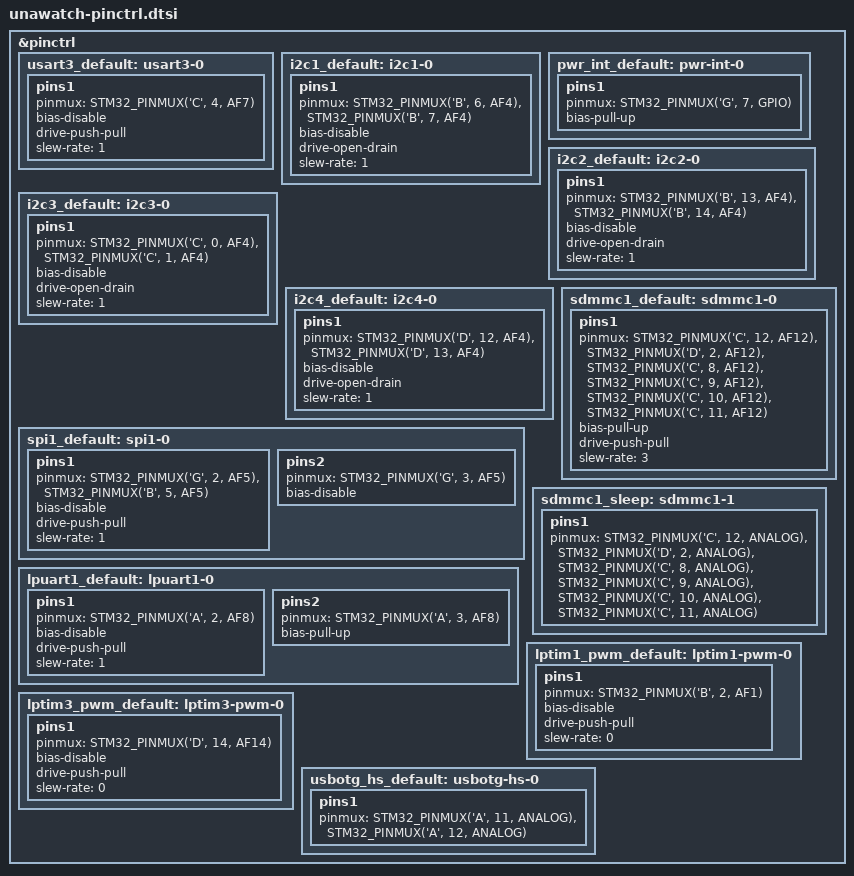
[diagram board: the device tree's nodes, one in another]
// SPDX-FileCopyrightText: 2026 Core Devices LLC
// SPDX-License-Identifier: (GPL-2.0-only OR BSD-2-Clause)

&pinctrl {
	// The debug log, TX only, to the USB-C connector through the USB_DAM switch
	usart3_default: usart3-0 {
		pins1 {
			pinmux = <STM32_PINMUX('C', 4, AF7)>; /* USART3_TX */
			bias-disable;
			drive-push-pull;
			slew-rate = <1>;
		};
	};

	// The main bus, external pull-ups: PMIC, fuel gauge, USB-PD, haptics, display EEPROM
	i2c1_default: i2c1-0 {
		pins1 {
			pinmux = <STM32_PINMUX('B', 6, AF4)>, /* I2C1_SCL */
				 <STM32_PINMUX('B', 7, AF4)>; /* I2C1_SDA */
			bias-disable;
			drive-open-drain;
			slew-rate = <1>;
		};
	};

	// PWR_INT_L: the PMIC's INTB and the STUSB4500's ALERT, open drain
	pwr_int_default: pwr-int-0 {
		pins1 {
			pinmux = <STM32_PINMUX('G', 7, GPIO)>;
			bias-pull-up;
		};
	};

	// The body module: PPG, barometer, EEPROM
	i2c2_default: i2c2-0 {
		pins1 {
			pinmux = <STM32_PINMUX('B', 13, AF4)>, /* I2C2_SCL */
				 <STM32_PINMUX('B', 14, AF4)>; /* I2C2_SDA */
			bias-disable;
			drive-open-drain;
			slew-rate = <1>;
		};
	};

	// The BLE module: its EEPROM
	i2c3_default: i2c3-0 {
		pins1 {
			pinmux = <STM32_PINMUX('C', 0, AF4)>, /* I2C3_SCL */
				 <STM32_PINMUX('C', 1, AF4)>; /* I2C3_SDA */
			bias-disable;
			drive-open-drain;
			slew-rate = <1>;
		};
	};

	// The GPS/IMU module: EEPROM, BMI270, BMM350
	i2c4_default: i2c4-0 {
		pins1 {
			pinmux = <STM32_PINMUX('D', 12, AF4)>, /* I2C4_SCL */
				 <STM32_PINMUX('D', 13, AF4)>; /* I2C4_SDA */
			bias-disable;
			drive-open-drain;
			slew-rate = <1>;
		};
	};

	// The BlueNRG-2, its chip select a GPIO
	spi1_default: spi1-0 {
		pins1 {
			pinmux = <STM32_PINMUX('G', 2, AF5)>, /* SPI1_SCK */
				 <STM32_PINMUX('B', 5, AF5)>; /* SPI1_MOSI */
			bias-disable;
			drive-push-pull;
			slew-rate = <1>;
		};

		pins2 {
			pinmux = <STM32_PINMUX('G', 3, AF5)>; /* SPI1_MISO */
			bias-disable;
		};
	};

	// The AG3335M GNSS
	lpuart1_default: lpuart1-0 {
		pins1 {
			pinmux = <STM32_PINMUX('A', 2, AF8)>; /* LPUART1_TX */
			bias-disable;
			drive-push-pull;
			slew-rate = <1>;
		};

		pins2 {
			pinmux = <STM32_PINMUX('A', 3, AF8)>; /* LPUART1_RX */
			bias-pull-up;
		};
	};

	// The eMMC, 4-bit
	sdmmc1_default: sdmmc1-0 {
		pins1 {
			pinmux = <STM32_PINMUX('C', 12, AF12)>, /* SDMMC1_CK */
				 <STM32_PINMUX('D', 2, AF12)>, /* SDMMC1_CMD */
				 <STM32_PINMUX('C', 8, AF12)>, /* SDMMC1_D0 */
				 <STM32_PINMUX('C', 9, AF12)>, /* SDMMC1_D1 */
				 <STM32_PINMUX('C', 10, AF12)>, /* SDMMC1_D2 */
				 <STM32_PINMUX('C', 11, AF12)>; /* SDMMC1_D3 */
			bias-pull-up;
			drive-push-pull;
			slew-rate = <3>;
		};
	};

	// The eMMC powered down: no pull-up feeds it
	sdmmc1_sleep: sdmmc1-1 {
		pins1 {
			pinmux = <STM32_PINMUX('C', 12, ANALOG)>, /* SDMMC1_CK */
				 <STM32_PINMUX('D', 2, ANALOG)>, /* SDMMC1_CMD */
				 <STM32_PINMUX('C', 8, ANALOG)>, /* SDMMC1_D0 */
				 <STM32_PINMUX('C', 9, ANALOG)>, /* SDMMC1_D1 */
				 <STM32_PINMUX('C', 10, ANALOG)>, /* SDMMC1_D2 */
				 <STM32_PINMUX('C', 11, ANALOG)>; /* SDMMC1_D3 */
		};
	};

	// The display VCOM: FRP on LPTIM1 CH1, XFRP on LPTIM3 CH1
	lptim1_pwm_default: lptim1-pwm-0 {
		pins1 {
			pinmux = <STM32_PINMUX('B', 2, AF1)>; /* LPTIM1_CH1, LCD_FRP */
			bias-disable;
			drive-push-pull;
			slew-rate = <0>;
		};
	};

	lptim3_pwm_default: lptim3-pwm-0 {
		pins1 {
			pinmux = <STM32_PINMUX('D', 14, AF14)>; /* LPTIM3_CH1, LCD_XFRP */
			bias-disable;
			drive-push-pull;
			slew-rate = <0>;
		};
	};

	// The USB OTG HS on its internal PHY
	usbotg_hs_default: usbotg-hs-0 {
		pins1 {
			pinmux = <STM32_PINMUX('A', 11, ANALOG)>, /* USB_OTG_HS_DM */
				 <STM32_PINMUX('A', 12, ANALOG)>; /* USB_OTG_HS_DP */
		};
	};
};
